AUTOSAR XML (schema 00048)
package /HuaweiMDC/FunctionalSoftware/Planning/Execution
  executable PlanningExecutable
    root sw component prototype PlanningRootSwComponent: application-type=PlanningApplicationSwComponent
package /HuaweiMDC/FunctionalSoftware/Planning/SwComponent
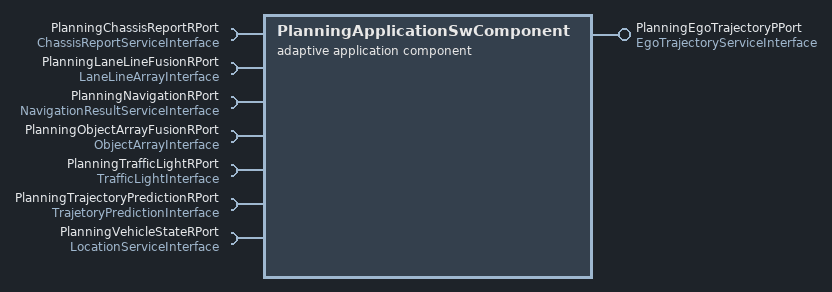
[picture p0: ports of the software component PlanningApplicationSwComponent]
  adaptive application sw component type PlanningApplicationSwComponent
    require port PlanningChassisReportRPort: required-interface=ChassisReportServiceInterface
    provide port PlanningEgoTrajectoryPPort: provided-interface=EgoTrajectoryServiceInterface
    6 x require port:
      PlanningLaneLineFusionRPort: required-interface=LaneLineArrayInterface
      PlanningNavigationRPort: required-interface=NavigationResultServiceInterface
      PlanningObjectArrayFusionRPort: required-interface=ObjectArrayInterface
      PlanningTrafficLightRPort: required-interface=TrafficLightInterface
      PlanningTrajectoryPredictionRPort: required-interface=TrajetoryPredictionInterface
      PlanningVehicleStateRPort: required-interface=LocationServiceInterface
